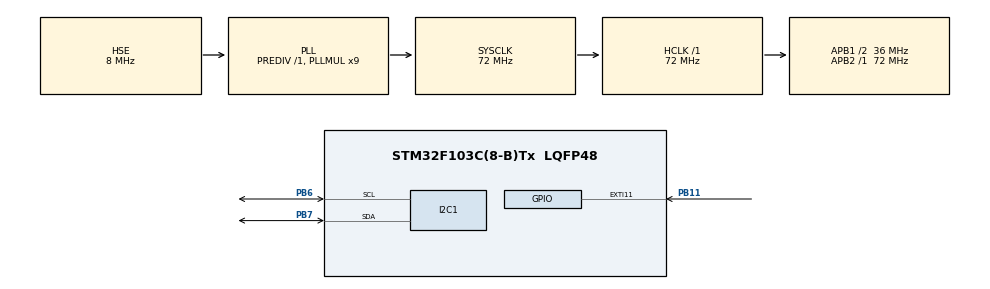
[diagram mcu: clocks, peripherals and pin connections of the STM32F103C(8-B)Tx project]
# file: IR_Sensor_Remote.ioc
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I2C1.I2C_Mode=I2C_Fast
Mcu.Family=STM32F1
Mcu.Name=STM32F103C(8-B)Tx
Mcu.Package=LQFP48
NVIC.EXTI15_10_IRQn=true\:0\:0\:false\:false\:true\:true\:true\:true
NVIC.PriorityGroup=NVIC_PRIORITYGROUP_4
PA13.Mode=Serial_Wire
PA13.Signal=SYS_JTMS-SWDIO
PA14.Mode=Serial_Wire
PA14.Signal=SYS_JTCK-SWCLK
PB11.GPIO_ModeDefaultEXTI=GPIO_MODE_IT_FALLING
PB11.Signal=GPXTI11
PB6.Mode=I2C
PB6.Signal=I2C1_SCL
PB7.Mode=I2C
PB7.Signal=I2C1_SDA
PD0-OSC_IN.Mode=HSE-External-Oscillator
PD0-OSC_IN.Signal=RCC_OSC_IN
PD1-OSC_OUT.Mode=HSE-External-Oscillator
PD1-OSC_OUT.Signal=RCC_OSC_OUT
ProjectManager.HeapSize=0x200
ProjectManager.StackSize=0x400
ProjectManager.TargetToolchain=STM32CubeIDE
RCC.AHBFreq_Value=72000000
RCC.APB1CLKDivider=RCC_HCLK_DIV2
RCC.APB1Freq_Value=36000000
RCC.APB1TimFreq_Value=72000000
RCC.APB2Freq_Value=72000000
RCC.APB2TimFreq_Value=72000000
RCC.HCLKFreq_Value=72000000
RCC.PLLMUL=RCC_PLL_MUL9
RCC.PLLSourceVirtual=RCC_PLLSOURCE_HSE
RCC.SYSCLKFreq_VALUE=72000000
RCC.SYSCLKSource=RCC_SYSCLKSOURCE_PLLCLK
RCC.USBFreq_Value=72000000
TIM1.Prescaler=71
VP_TIM1_VS_ClockSourceINT.Mode=Internal
board=custom

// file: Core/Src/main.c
/* USER CODE BEGIN Header */
/**
  ******************************************************************************
  * @file           : main.c
  * @brief          : Main program body
  ******************************************************************************
  * @attention
  *
  * Copyright (c) 2022 STMicroelectronics.
  * All rights reserved.
  *
  * This software is licensed under terms that can be found in the LICENSE file
  * in the root directory of this software component.
  * If no LICENSE file comes with this software, it is provided AS-IS.
  *
  ******************************************************************************
  */
/* USER CODE END Header */
#include "main.h"

/* USER CODE BEGIN Includes */
#include "fonts.h"
#include "ssd1306.h"
/* USER CODE END Includes */

I2C_HandleTypeDef hi2c1;

TIM_HandleTypeDef htim1;

/* USER CODE BEGIN PV */
uint32_t tempCode;
uint8_t bitIndex;
uint8_t cmd;
uint8_t cmdli;
uint32_t code;
/* USER CODE END PV */

void SystemClock_Config(void);
static void MX_GPIO_Init(void);
static void MX_TIM1_Init(void);
static void MX_I2C1_Init(void);

int main(void)
{

  /* MCU Configuration--------------------------------------------------------*/

  /* Reset of all peripherals, Initializes the Flash interface and the Systick. */
  HAL_Init();

  /* Configure the system clock */
  SystemClock_Config();

  /* Initialize all configured peripherals */
  MX_GPIO_Init();
  MX_TIM1_Init();
  MX_I2C1_Init();
  /* USER CODE BEGIN 2 */
	SSD1306_Init();
	HAL_TIM_Base_Start(&htim1);
	__HAL_TIM_SET_COUNTER(&htim1, 0);

  /* USER CODE END 2 */

  /* Infinite loop */
  while (1)
  {

  }
}

void SystemClock_Config(void)
{
  RCC_OscInitTypeDef RCC_OscInitStruct = {0};
  RCC_ClkInitTypeDef RCC_ClkInitStruct = {0};

  /** Initializes the RCC Oscillators according to the specified parameters
  * in the RCC_OscInitTypeDef structure.
  */
  RCC_OscInitStruct.OscillatorType = RCC_OSCILLATORTYPE_HSE;
  RCC_OscInitStruct.HSEState = RCC_HSE_ON;
  RCC_OscInitStruct.HSEPredivValue = RCC_HSE_PREDIV_DIV1;
  RCC_OscInitStruct.HSIState = RCC_HSI_ON;
  RCC_OscInitStruct.PLL.PLLState = RCC_PLL_ON;
  RCC_OscInitStruct.PLL.PLLSource = RCC_PLLSOURCE_HSE;
  RCC_OscInitStruct.PLL.PLLMUL = RCC_PLL_MUL9;
  if (HAL_RCC_OscConfig(&RCC_OscInitStruct) != HAL_OK)
  {
    Error_Handler();
  }

  /** Initializes the CPU, AHB and APB buses clocks
  */
  RCC_ClkInitStruct.ClockType = RCC_CLOCKTYPE_HCLK|RCC_CLOCKTYPE_SYSCLK
                              |RCC_CLOCKTYPE_PCLK1|RCC_CLOCKTYPE_PCLK2;
  RCC_ClkInitStruct.SYSCLKSource = RCC_SYSCLKSOURCE_PLLCLK;
  RCC_ClkInitStruct.AHBCLKDivider = RCC_SYSCLK_DIV1;
  RCC_ClkInitStruct.APB1CLKDivider = RCC_HCLK_DIV2;
  RCC_ClkInitStruct.APB2CLKDivider = RCC_HCLK_DIV1;

  if (HAL_RCC_ClockConfig(&RCC_ClkInitStruct, FLASH_LATENCY_2) != HAL_OK)
  {
    Error_Handler();
  }
}

static void MX_I2C1_Init(void)
{

  hi2c1.Instance = I2C1;
  hi2c1.Init.ClockSpeed = 400000;
  hi2c1.Init.DutyCycle = I2C_DUTYCYCLE_2;
  hi2c1.Init.OwnAddress1 = 0;
  hi2c1.Init.AddressingMode = I2C_ADDRESSINGMODE_7BIT;
  hi2c1.Init.DualAddressMode = I2C_DUALADDRESS_DISABLE;
  hi2c1.Init.OwnAddress2 = 0;
  hi2c1.Init.GeneralCallMode = I2C_GENERALCALL_DISABLE;
  hi2c1.Init.NoStretchMode = I2C_NOSTRETCH_DISABLE;
  if (HAL_I2C_Init(&hi2c1) != HAL_OK)
  {
    Error_Handler();
  }

}

static void MX_TIM1_Init(void)
{

  TIM_ClockConfigTypeDef sClockSourceConfig = {0};
  TIM_MasterConfigTypeDef sMasterConfig = {0};

  htim1.Instance = TIM1;
  htim1.Init.Prescaler = 71;
  htim1.Init.CounterMode = TIM_COUNTERMODE_UP;
  htim1.Init.Period = 65535;
  htim1.Init.ClockDivision = TIM_CLOCKDIVISION_DIV1;
  htim1.Init.RepetitionCounter = 0;
  htim1.Init.AutoReloadPreload = TIM_AUTORELOAD_PRELOAD_DISABLE;
  if (HAL_TIM_Base_Init(&htim1) != HAL_OK)
  {
    Error_Handler();
  }
  sClockSourceConfig.ClockSource = TIM_CLOCKSOURCE_INTERNAL;
  if (HAL_TIM_ConfigClockSource(&htim1, &sClockSourceConfig) != HAL_OK)
  {
    Error_Handler();
  }
  sMasterConfig.MasterOutputTrigger = TIM_TRGO_RESET;
  sMasterConfig.MasterSlaveMode = TIM_MASTERSLAVEMODE_DISABLE;
  if (HAL_TIMEx_MasterConfigSynchronization(&htim1, &sMasterConfig) != HAL_OK)
  {
    Error_Handler();
  }

}

static void MX_GPIO_Init(void)
{
  GPIO_InitTypeDef GPIO_InitStruct = {0};

  /* GPIO Ports Clock Enable */
  __HAL_RCC_GPIOD_CLK_ENABLE();
  __HAL_RCC_GPIOB_CLK_ENABLE();
  __HAL_RCC_GPIOA_CLK_ENABLE();

  /*Configure GPIO pin : PB11 */
  GPIO_InitStruct.Pin = GPIO_PIN_11;
  GPIO_InitStruct.Mode = GPIO_MODE_IT_FALLING;
  GPIO_InitStruct.Pull = GPIO_NOPULL;
  HAL_GPIO_Init(GPIOB, &GPIO_InitStruct);

  /* EXTI interrupt init*/
  HAL_NVIC_SetPriority(EXTI15_10_IRQn, 0, 0);
  HAL_NVIC_EnableIRQ(EXTI15_10_IRQn);

}

/* USER CODE BEGIN 4 */
void HAL_GPIO_EXTI_Callback(uint16_t GPIO_Pin) {
	if (GPIO_Pin == GPIO_PIN_11) {
		if (__HAL_TIM_GET_COUNTER(&htim1) > 8000) {
			tempCode = 0;
			bitIndex = 0;
		} else if (__HAL_TIM_GET_COUNTER(&htim1) > 1700) {
			tempCode |= (1UL << (31 - bitIndex));   // write 1
			bitIndex++;
		} else if (__HAL_TIM_GET_COUNTER(&htim1) > 1000) {
			tempCode &= ~(1UL << (31 - bitIndex));  // write 0
			bitIndex++;
		}
		if (bitIndex == 32) {
			cmdli = ~tempCode; // Logical inverted last 8 bits
			cmd = tempCode >> 8; // Second last 8 bits
			if (cmdli == cmd) // Check for errors
					{
				code = tempCode; // If no bit errors
				// Do your main work HERE
//no display
//        SSD1306_Clear();
//        SSD1306_GotoXY (0, 20);
				char snum[10];
				itoa(code, snum, 10);
//no display
//        SSD1306_Puts (snum, &Font_11x18, 1);
//        SSD1306_UpdateScreen();
			}
			bitIndex = 0;
		}
		__HAL_TIM_SET_COUNTER(&htim1, 0);
	}
}
/*
void HAL_GPIO_EXTI_Callback(uint16_t GPIO_Pin) {
	if (GPIO_Pin == GPIO_PIN_11) {
		if (__HAL_TIM_GET_COUNTER(&htim1) > 8000) {
			tempCode = 0;
			bitIndex = 0;
		} else if (__HAL_TIM_GET_COUNTER(&htim1) > 1700) {
			tempCode |= (1UL << (31 - bitIndex));   // write 1
			bitIndex++;
		} else if (__HAL_TIM_GET_COUNTER(&htim1) > 1000) {
			tempCode &= ~(1UL << (31 - bitIndex));  // write 0
			bitIndex++;
		}
		if (bitIndex == 32) {
			cmdli = ~tempCode; // Logical inverted last 8 bits
			cmd = tempCode >> 8; // Second last 8 bits
			if (cmdli == cmd) // Check for errors
					{
				code = tempCode; // If no bit errors
				// Do your main work HERE
				SSD1306_Clear();
				SSD1306_GotoXY(0, 20);
				switch (code) {
				case (16753245):
					SSD1306_Puts("CH-", &Font_16x26, 1);
					break;

				case (16736925):
					SSD1306_Puts("CH", &Font_16x26, 1);
					break;

				case (16769565):
					SSD1306_Puts("CH+", &Font_16x26, 1);
					break;

				case (16720605):
					SSD1306_Puts("|<<", &Font_16x26, 1);
					break;

				case (16712445):
					SSD1306_Puts(">>|", &Font_16x26, 1);
					break;

				case (16761405):
					SSD1306_Puts(">||", &Font_16x26, 1);
					break;

				case (16769055):
					SSD1306_Puts("-", &Font_16x26, 1);
					break;

				case (16754775):
					SSD1306_Puts("+", &Font_16x26, 1);
					break;

				case (16748655):
					SSD1306_Puts("EQ", &Font_16x26, 1);
					break;

				case (16738455):
					SSD1306_Puts("0", &Font_16x26, 1);
					break;

				case (16750695):
					SSD1306_Puts("100+", &Font_16x26, 1);
					break;

				case (16756815):
					SSD1306_Puts("200+", &Font_16x26, 1);
					break;

				case (16724175):
					SSD1306_Puts("1", &Font_16x26, 1);
					break;

				case (16718055):
					SSD1306_Puts("2", &Font_16x26, 1);
					break;

				case (16743045):
					SSD1306_Puts("3", &Font_16x26, 1);
					break;

				case (16716015):
					SSD1306_Puts("4", &Font_16x26, 1);
					break;

				case (16726215):
					SSD1306_Puts("5", &Font_16x26, 1);
					break;

				case (16734885):
					SSD1306_Puts("6", &Font_16x26, 1);
					break;

				case (16728765):
					SSD1306_Puts("7", &Font_16x26, 1);
					break;

				case (16730805):
					SSD1306_Puts("8", &Font_16x26, 1);
					break;

				case (16732845):
					SSD1306_Puts("9", &Font_16x26, 1);
					break;

				default:
					break;
				}
				SSD1306_UpdateScreen();
			}
			bitIndex = 0;
		}
		__HAL_TIM_SET_COUNTER(&htim1, 0);
	}
}
*/
/* USER CODE END 4 */

void Error_Handler(void)
{
  __disable_irq();
  while (1)
  {
  }
}
